AUTOSAR XML (schema 4-0-3)
standard types defined: Boolean, UInt32
package /AUTOSAR_Platform/DataConstrs
  range DC_Boolean: raw 0..1
package /PATAC/MSM/ComponentTypes
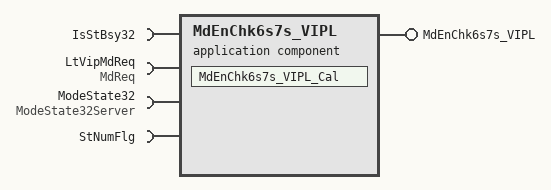
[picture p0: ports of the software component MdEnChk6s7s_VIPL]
  application sw component type MdEnChk6s7s_VIPL
    provide port MdEnChk6s7s_VIPL: server-com-spec{operation=Cal, queue-length=1}, provided-interface=MdEnChk6s7s_VIPL
    4 x require port:
      IsStBsy32: required-com-specs=[IsStBsy32/Clear, IsStBsy32/Get, IsStBsy32/Set], required-interface=IsStBsy32
      LtVipMdReq: nonqueued-receiver-com-spec{data-element=Val, filter=data-filter-type=ALWAYS, init-value=0}, required-interface=MdReq
      ModeState32: required-com-specs=[ModeState32Server/Clear, ModeState32Server/Get, ModeState32Server/Set], required-interface=ModeState32Server
      StNumFlg: required-interface=StNumFlg
        required-com-specs:
          data-element=Is4s, filter=data-filter-type=ALWAYS, init-value=0
          data-element=Is6s, filter=data-filter-type=ALWAYS, init-value=0
          data-element=Is6s7s, filter=data-filter-type=ALWAYS, init-value=0
          data-element=Is7s, filter=data-filter-type=ALWAYS, init-value=0
    behavior MdEnChk6s7s_VIPL_InternalBehavior
      operation invoked event OIT_MdEnChk6s7s_VIPL_Cal_MdEnChk6s7s_VIPL_Cal: start-on-event=MdEnChk6s7s_VIPL_Cal, operation=MdEnChk6s7s_VIPL.Cal
      runnable MdEnChk6s7s_VIPL_Cal
        data-receive-point-by-arguments:
          access REC_LtVipMdReq_Val: accessed-variable=LtVipMdReq.Val
          access REC_StNumFlg_Is6s: accessed-variable=StNumFlg.Is6s
          access REC_StNumFlg_Is7s: accessed-variable=StNumFlg.Is7s
        sync call SC_IsStBsy32_Get: operation=IsStBsy32.Get, timeout=0
        sync call SC_IsStBsy32_Set: operation=IsStBsy32.Set, timeout=0
        sync call SC_ModeState32_Set: operation=ModeState32.Set, timeout=0
  swc implementation MdEnChk6s7s_VIPL_Implementation: behavior=MdEnChk6s7s_VIPL_InternalBehavior
    code-descriptors:
      code Default: artifact-descriptors=autosar-engineering-object={short-label=Default, category=SWSRC}
package /PATAC/MSM/ModeAdjust/PortInterface
  client server interface IsStBsy32
    operation Clear
      arg ClearBit: type=UInt32, direction=IN, server-argument-impl-policy=USE-ARGUMENT-TYPE
    operation Get
      arg IsStBsy32Bit: type=UInt32, direction=OUT, server-argument-impl-policy=USE-ARGUMENT-TYPE
    operation Set
      arg SetBit: type=UInt32, direction=IN, server-argument-impl-policy=USE-ARGUMENT-TYPE
  client server interface MdEnChk6s7s_VIPL
    operation Cal
  client server interface ModeState32Server
    operation Clear
      arg ClearBit: type=UInt32, direction=IN, server-argument-impl-policy=USE-ARGUMENT-TYPE
    operation Get
      arg MdEn32: type=UInt32, direction=OUT, server-argument-impl-policy=USE-ARGUMENT-TYPE
    operation Set
      arg SetBit: type=UInt32, direction=IN, server-argument-impl-policy=USE-ARGUMENT-TYPE
  sender receiver interface MdReq: invalidation-policy{data-element=Val, handle-invalid=DONT-INVALIDATE}
    data Val: type=Boolean
  sender receiver interface StNumFlg
    4 x data, all with type=Boolean:
      Is4s
      Is6s
      Is6s7s
      Is7s
    invalidation-policys:
      data-element=Is7s, handle-invalid=DONT-INVALIDATE
      data-element=Is6s, handle-invalid=DONT-INVALIDATE
      data-element=Is4s, handle-invalid=DONT-INVALIDATE
      data-element=Is6s7s, handle-invalid=DONT-INVALIDATE
